# MSP430FR5962 register map
File version: 2.1
CPU: MSP430FR5962 r2p1, little endian, MPU, no FPU, 3 interrupt priority bits
Registers are 16-bit, read-write, reset 0x0 unless marked. A register's access mark holds for its fields unless they carry their own. Offsets are from the block's base; [hi:lo] are bit positions; 'fields as' and 'values as' point back to an identical list.

## MPU
Base 0x000005A0
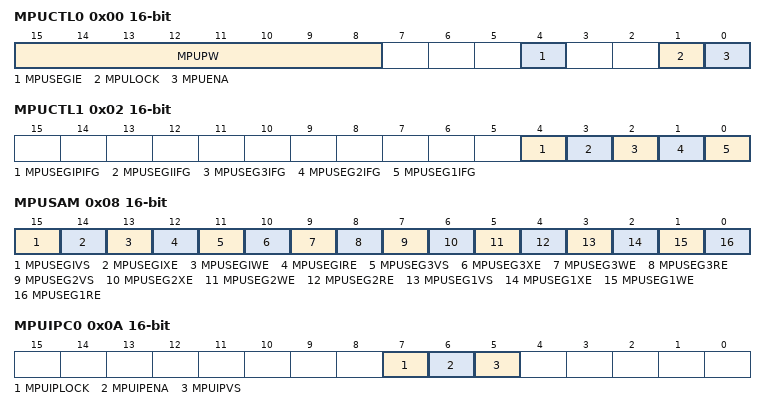
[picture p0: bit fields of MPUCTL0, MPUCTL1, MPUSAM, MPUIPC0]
0x00 MPUCTL0 — Memory Protection Unit Control 0
  [15:8] MPUPW — [15:8] MPU Password
  [4] MPUSEGIE — [4:4] Enable NMI Event if a Segment violation
    0=DISABLE (Segment violation interrupt disabled); 1=ENABLE (Segment violation interrupt enabled)
  [1] MPULOCK — [1:1] MPU Lock
    0=OPEN; 1=LOCK (Locked)
  [0] MPUENA — [0:0] MPU Enable
    0=DISABLE (Disabled); 1=ENABLE (Enabled)
0x02 MPUCTL1 — Memory Protection Unit Control 1
  [4] MPUSEGIPIFG — [4:4] IP Encapsulation Access Violation Interrupt Flag
    0=MPUSEG1IFG_0 (No interrupt pending); 1=MPUSEG1IFG_1 (Interrupt pending)
  [3] MPUSEGIIFG — [3:3] User Information Memory Violation Interrupt Flag
    0=No interrupt pending; 1=Interrupt pending
  [2] MPUSEG3IFG — [2:2] Main Memory Segment 3 Violation Interrupt Flag
    values as MPUSEGIPIFG
  [1] MPUSEG2IFG — [1:1] Main Memory Segment 2 Violation Interrupt Flag
    0=No interrupt pending; 1=Interrupt pending
  [0] MPUSEG1IFG — [0:0] Main Memory Segment 1 Violation Interrupt Flag
    0=No interrupt pending; 1=Interrupt pending
0x04 MPUSEGB2 — Memory Protection Unit Segmentation Border 2 Register
0x06 MPUSEGB1 — Memory Protection Unit Segmentation Border 1 Register
0x08 MPUSAM — Memory Protection Unit Segmentation Access Management Register
  [15] MPUSEGIVS — [15:15] MPU User Information Memory Segment Violation Select
    0=Violation in User Information Memory asserts the MPUSEGIIFG bit and executes a SNMI if enabled by MPUSEGIE =1; 1=Violation in User Information Memory asserts the MPUSEGIIFG bit and executes a PUC
  [14] MPUSEGIXE — [14:14] MPU User Information Memory Segment Execute Enable
    0=DISABLE (Execute code on User Information Memory causes a violation); 1=ENABLE (Execute code on User Information Memory is allowed)
  [13] MPUSEGIWE — [13:13] MPU User Information Memory Segment Write Enable.
    0=DISABLE (Write on User Information Memory causes a violation); 1=ENABLE (Write on User Information Memory is allowed)
  [12] MPUSEGIRE — [12:12] MPU User Information Memory Segment Read Enable
    0=DISABLE (Read on User Information Memory causes a violation if MPUSEGIWE=MPUSEGIXE=0); 1=ENABLE (Read on User Information Memory is allowed)
  [11] MPUSEG3VS — [11:11] MPU Main Memory Segment 3 Violation Select
    0=Violation in Main Memory Segment 3 asserts the MPUSEG3IFG bit and executes a SNMI if enabled by MPUSEGIE = 1; 1=Violation in Main Memory Segment 3 asserts the MPUSEG3IFG bit and executes a PUC
  [10] MPUSEG3XE — [10:10] MPU Main Memory Segment 3 Execute Enable
    0=DISABLE (Execute code on Main Memory Segment 3 causes a violation); 1=ENABLE (Execute code on Main Memory Segment 3 is allowed)
  [9] MPUSEG3WE — [9:9] MPU Main Memory Segment 3 Write Enable
    0=DISABLE (Write on Main Memory Segment 3 causes a violation); 1=ENABLE (Write on Main Memory Segment 3 is allowed)
  [8] MPUSEG3RE — [8:8] MPU Main Memory Segment 3 Read Enable
    0=DISABLE (Read on Main Memory Segment 3 causes a violation if MPUSEG3WE = MPUSEG3XE = 0); 1=ENABLE (Read on Main Memory Segment 3 is allowed)
  [7] MPUSEG2VS — [7:7] MPU Main Memory Segment 2 Violation Select
    0=Violation in Main Memory Segment 2 asserts the MPUSEG2IFG bit and executes a SNMI if enabled by MPUSEGIE = 1; 1=Violation in Main Memory Segment 2 asserts the MPUSEG2IFG bit and executes a PUC
  [6] MPUSEG2XE — [6:6] MPU Main Memory Segment 2 Execute Enable
    0=DISABLE (Execute code on Main Memory Segment 2 causes a violation); 1=ENABLE (Execute code on Main Memory Segment 2 is allowed)
  [5] MPUSEG2WE — [5:5] MPU Main Memory Segment 2 Write Enable
    0=DISABLE (Write on Main Memory Segment 2 causes a violation); 1=ENABLE (Write on Main Memory Segment 2 is allowed)
  [4] MPUSEG2RE — [4:4] MPU Main Memory Segment 2 Read Enable
    0=DISABLE (Read on Main Memory Segment 2 causes a violation if MPUSEG2WE = MPUSEG2XE = 0); 1=ENABLE (Read on Main Memory Segment 2 is allowed)
  [3] MPUSEG1VS — [3:3] MPU Main Memory Segment 1 Violation Select
    0=Violation in Main Memory Segment 1 asserts the MPUSEG1IFG bit and executes a SNMI if enabled by MPUSEGIE = 1; 1=Violation in Main Memory Segment 1 asserts the MPUSEG1IFG bit and executes a PUC
  [2] MPUSEG1XE — [2:2] MPU Main Memory Segment 1 Execute Enable
    0=DISABLE (Execute code on Main Memory Segment 1 causes a violation); 1=ENABLE (Execute code on Main Memory Segment 1 is allowed)
  [1] MPUSEG1WE — [1:1] MPU Main Memory Segment 1 Write Enable
    0=DISABLE (Write on Main Memory Segment 1 causes a violation); 1=ENABLE (Write on Main Memory Segment 1 is allowed)
  [0] MPUSEG1RE — [0:0] MPU Main Memory Segment 1 Read Enable
    0=DISABLE (Read on Main Memory Segment 1 causes a violation if MPUSEG1WE = MPUSEG1XE = 0); 1=ENABLE (Read on Main Memory Segment 1 is allowed)
0x0A MPUIPC0 — Memory Protection Unit IP Control 0 Register
  [7] MPUIPLOCK — [7:7] MPU IP Encapsulation Lock
    0=OPEN; 1=LOCK (Locked)
  [6] MPUIPENA — [6:6] MPU IP Encapsulation Enable
    0=DISABLE (Disabled); 1=ENABLE (Enabled)
  [5] MPUIPVS — [5:5] MPU IP Encapsulation segment Violation Select
    0=Violation in Main Memory Segment 1 asserts the MPUSEGPIFG bit and executes a SNMI if enabled by MPUSEGIE = 1; 1=Violation in Main Memory Segment 1 asserts the MPUSEGPIFG bit and executes a PUC
0x0C MPUIPSEGB2 — Memory Protection Unit IP Encapsulation Segment Border 2 Register
0x0E MPUIPSEGB1 — Memory Protection Unit IP Encapsulation Segment Border 1 Register
